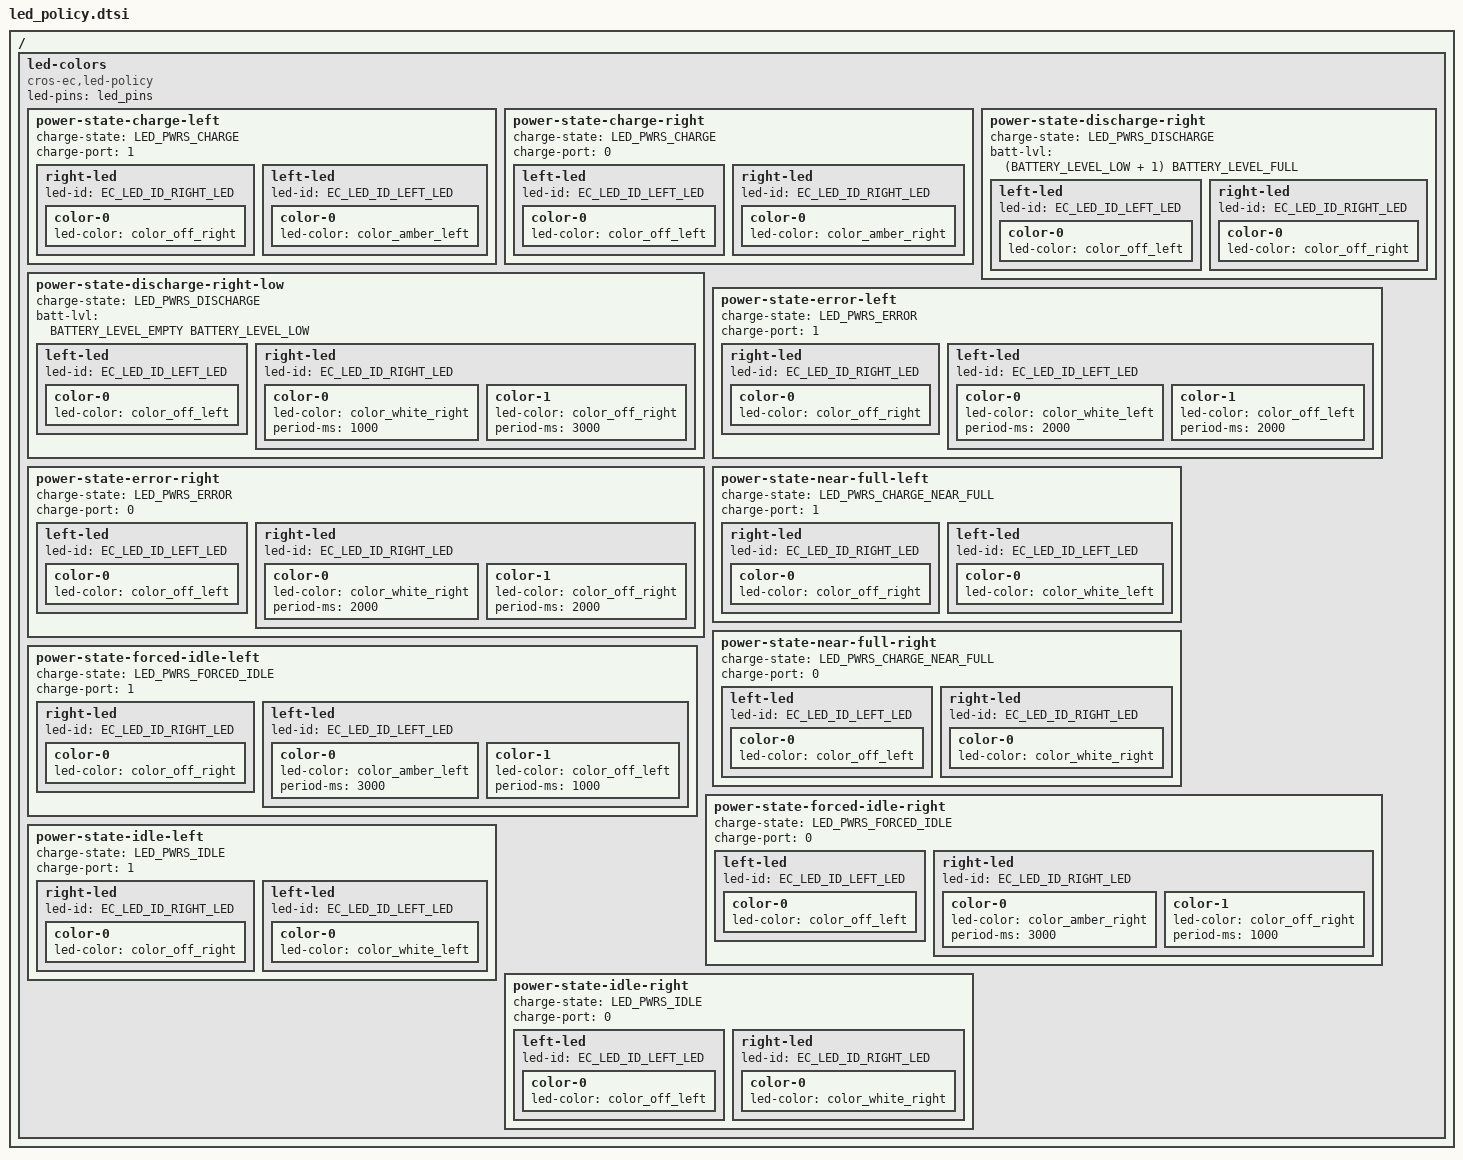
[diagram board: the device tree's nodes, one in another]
#include <dt-bindings/battery.h>

/ {
	led-colors {
		compatible = "cros-ec,led-policy";
		led-pins = <&led_pins>;

		power-state-charge-left {
			charge-state = "LED_PWRS_CHARGE";
			charge-port = <1>; /* Left port */

			right-led {
				led-id = "EC_LED_ID_RIGHT_LED";
				/* Turn off the right LED */
				color-0 {
					led-color = <&color_off_right>;
				};
			};
			left-led {
				led-id = "EC_LED_ID_LEFT_LED";
				/* Left LED to Amber */
				color-0 {
					led-color = <&color_amber_left>;
				};
			};
		};

		power-state-charge-right {
			charge-state = "LED_PWRS_CHARGE";
			charge-port = <0>; /* Right port */

			left-led {
				led-id = "EC_LED_ID_LEFT_LED";
				/* Turn off the left LED */
				color-0 {
					led-color = <&color_off_left>;
				};
			};
			right-led {
				led-id = "EC_LED_ID_RIGHT_LED";
				/* Right LED to Amber */
				color-0 {
					led-color = <&color_amber_right>;
				};
			};
		};

		power-state-discharge-right-low {
			charge-state = "LED_PWRS_DISCHARGE";
			/* Battery percent range (>= Empty, <= Low) */
			batt-lvl = <BATTERY_LEVEL_EMPTY BATTERY_LEVEL_LOW>;

			left-led {
				led-id = "EC_LED_ID_LEFT_LED";
				/* Turn off the left LED */
				color-0 {
					led-color = <&color_off_left>;
				};
			};
			right-led {
				led-id = "EC_LED_ID_RIGHT_LED";
				/* Right LED - White 1 sec, off 3 sec */
				color-0 {
					led-color = <&color_white_right>;
					period-ms = <1000>;
				};
				color-1 {
					led-color = <&color_off_right>;
					period-ms = <3000>;
				};
			};
		};

		power-state-discharge-right {
			charge-state = "LED_PWRS_DISCHARGE";
			/* Battery percent range (> Low, <= Full) */
			batt-lvl = <(BATTERY_LEVEL_LOW + 1) BATTERY_LEVEL_FULL>;

			left-led {
				led-id = "EC_LED_ID_LEFT_LED";
				/* Turn off the left LED */
				color-0 {
					led-color = <&color_off_left>;
				};
			};
			right-led {
				led-id = "EC_LED_ID_RIGHT_LED";
				/* Turn off the right LED */
				color-0 {
					led-color = <&color_off_right>;
				};
			};
		};

		power-state-error-left {
			charge-state = "LED_PWRS_ERROR";
			charge-port = <1>; /* Left port */

			right-led {
				led-id = "EC_LED_ID_RIGHT_LED";
				/* Turn off the right LED */
				color-0 {
					led-color = <&color_off_right>;
				};
			};
			left-led {
				led-id = "EC_LED_ID_LEFT_LED";
				/* Left LED - White 2 sec, off 2 sec */
				color-0 {
					led-color = <&color_white_left>;
					period-ms = <2000>;
				};
				color-1 {
					led-color = <&color_off_left>;
					period-ms = <2000>;
				};
			};
		};

		power-state-error-right {
			charge-state = "LED_PWRS_ERROR";
			charge-port = <0>; /* Right port */

			left-led {
				led-id = "EC_LED_ID_LEFT_LED";
				/* Turn off the left LED */
				color-0 {
					led-color = <&color_off_left>;
				};
			};
			right-led {
				led-id = "EC_LED_ID_RIGHT_LED";
				/* Right LED - White 2 sec, off 2 sec */
				color-0 {
					led-color = <&color_white_right>;
					period-ms = <2000>;
				};
				color-1 {
					led-color = <&color_off_right>;
					period-ms = <2000>;
				};
			};
		};

		power-state-near-full-left {
			charge-state = "LED_PWRS_CHARGE_NEAR_FULL";
			charge-port = <1>; /* Left port */

			right-led {
				led-id = "EC_LED_ID_RIGHT_LED";
				/* Turn off the right LED */
				color-0 {
					led-color = <&color_off_right>;
				};
			};
			left-led {
				led-id = "EC_LED_ID_LEFT_LED";
				/* Left LED to White */
				color-0 {
					led-color = <&color_white_left>;
				};
			};
		};

		power-state-near-full-right {
			charge-state = "LED_PWRS_CHARGE_NEAR_FULL";
			charge-port = <0>; /* Right port */

			left-led {
				led-id = "EC_LED_ID_LEFT_LED";
				/* Turn off the left LED */
				color-0 {
					led-color = <&color_off_left>;
				};
			};
			right-led {
				led-id = "EC_LED_ID_RIGHT_LED";
				/* Right LED to White */
				color-0 {
					led-color = <&color_white_right>;
				};
			};
		};

		power-state-forced-idle-left {
			charge-state = "LED_PWRS_FORCED_IDLE";
			charge-port = <1>; /* Left port */

			right-led {
				led-id = "EC_LED_ID_RIGHT_LED";
				/* Turn off the right LED */
				color-0 {
					led-color = <&color_off_right>;
				};
			};
			left-led {
				led-id = "EC_LED_ID_LEFT_LED";
				/* Left LED - Amber 3 sec, Off 1 sec */
				color-0 {
					led-color = <&color_amber_left>;
					period-ms = <3000>;
				};
				color-1 {
					led-color = <&color_off_left>;
					period-ms = <1000>;
				};
			};
		};

		power-state-forced-idle-right {
			charge-state = "LED_PWRS_FORCED_IDLE";
			charge-port = <0>; /* Right port */

			left-led {
				led-id = "EC_LED_ID_LEFT_LED";
				/* Turn off the left LED */
				color-0 {
					led-color = <&color_off_left>;
				};
			};
			right-led {
				led-id = "EC_LED_ID_RIGHT_LED";
				/* Right LED - Amber 3 sec, Off 1 sec */
				color-0 {
					led-color = <&color_amber_right>;
					period-ms = <3000>;
				};
				color-1 {
					led-color = <&color_off_right>;
					period-ms = <1000>;
				};
			};
		};

		power-state-idle-left {
			charge-state = "LED_PWRS_IDLE";
			charge-port = <1>; /* Left port */

			right-led {
				led-id = "EC_LED_ID_RIGHT_LED";
				/* Turn off the right LED */
				color-0 {
					led-color = <&color_off_right>;
				};
			};
			left-led {
				led-id = "EC_LED_ID_LEFT_LED";
				/* Left LED to White */
				color-0 {
					led-color = <&color_white_left>;
				};
			};
		};

		power-state-idle-right {
			charge-state = "LED_PWRS_IDLE";
			charge-port = <0>; /* Right port */

			left-led {
				led-id = "EC_LED_ID_LEFT_LED";
				/* Turn off the left LED */
				color-0 {
					led-color = <&color_off_left>;
				};
			};
			right-led {
				led-id = "EC_LED_ID_RIGHT_LED";
				/* Right LED to White */
				color-0 {
					led-color = <&color_white_right>;
				};
			};
		};
	};
};
